# GD32E25x register map
File version: 1.0
CPU: CM23 r1p0, little endian, no MPU, no FPU, 2 interrupt priority bits
Registers are 32-bit, read-write, reset 0x0 unless marked. A register's access mark holds for its fields unless they carry their own. Offsets are from the block's base; [hi:lo] are bit positions; {n}, {i} and the like mark numbered series.

## GPIOB — General-purpose I/Os
Base 0x48000400
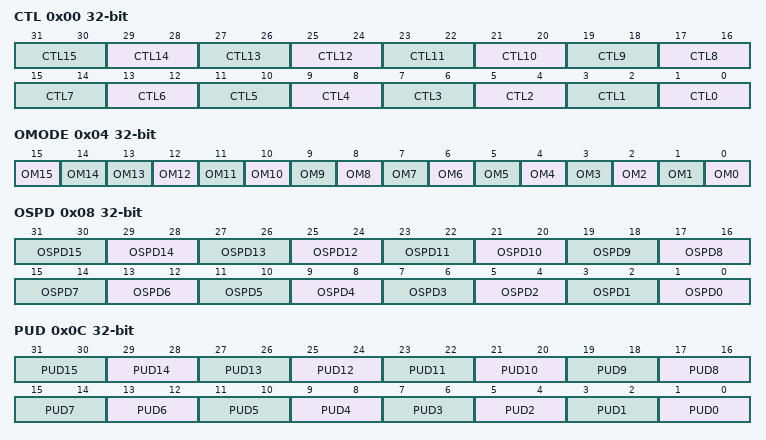
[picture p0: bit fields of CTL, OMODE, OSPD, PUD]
0x00 CTL — GPIO port control register
  [2n+1:2n] CTL{n} (n=0..15) — Pin {n} configuration bits
0x04 OMODE — GPIO port output type register
  [15] OM15 — Pin 15 output mode bit
  [14] OM14 — Pin 15 output mode bit
  [n] OM{n} (n=0..13) — Pin {n} output mode bit
0x08 OSPD — GPIO port output speed register
  [2n+1:2n] OSPD{n} (n=0..15) — Pin {n} output max speed bits
0x0C PUD — GPIO port pull-up/pull-down register
  [2n+1:2n] PUD{n} (n=0..15) — Pin {n} pull-up or pull-down bits
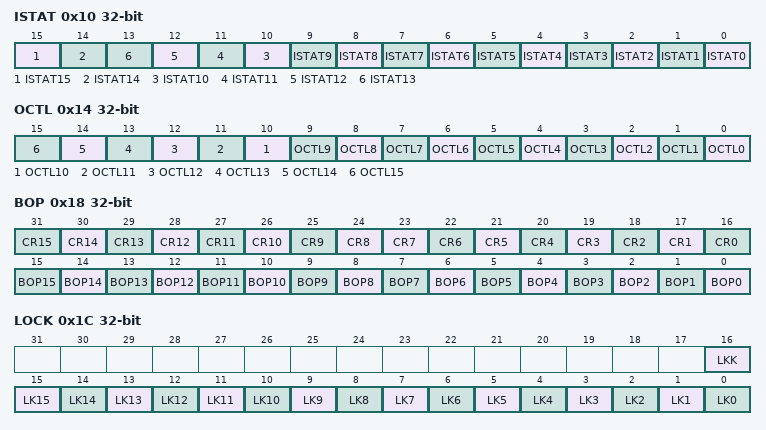
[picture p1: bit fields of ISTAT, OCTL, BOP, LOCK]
0x10 ISTAT ro — GPIO port input data register
  [15] ISTAT15 — Port input status
  [14] ISTAT14 — PPort input status
  [n] ISTAT{n} (n=0..13) — Port input status
0x14 OCTL — GPIO port output data register
  [n] OCTL{n} (n=0..15) — Port output data
0x18 BOP wo — GPIO port bit set/reset register
  [n+16] CR{n} (n=8..15) — Pin {n} reset bit
  [23] CR7 — Pin 7 reset bit)
  [n+16] CR{n} (n=2..6) — Pin {n} reset bit
  [17] CR1 — Pin 2 reset bit
  [16] CR0 — Pin 0 reset bit
  [n] BOP{n} (n=0..15) — Pin {n} set bit
0x1C LOCK — GPIO port configuration lock register
  [16] LKK — Lock key
  [n] LK{n} (n=0..15) — Port A lock bit {n}
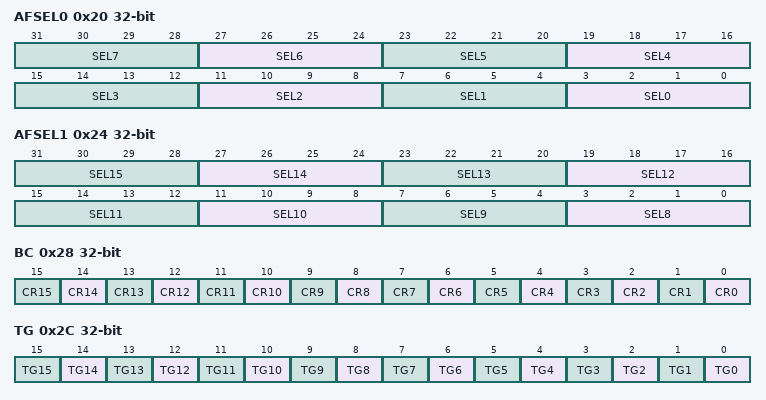
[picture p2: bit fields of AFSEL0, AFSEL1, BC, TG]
0x20 AFSEL0 — GPIO alternate function low register
  [4n+3:4n] SEL{n} (n=0..7) — Pin {n} alternate function selected
0x24 AFSEL1 — GPIO alternate function register 1
  [4n-29:4n-32] SEL{n} (n=8..15) — Pin {n} alternate function selected
0x28 BC wo — Port bit reset register
  [n] CR{n} (n=0..15) — Port cleat bit
0x2C TG wo — Port bit toggle register
  [n] TG{n} (n=0..15) — Port toggle bit
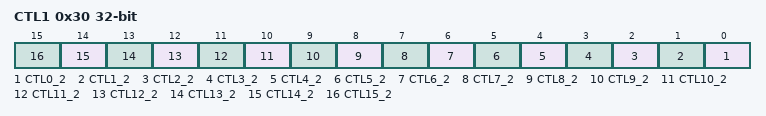
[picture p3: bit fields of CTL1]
0x30 CTL1 — GPIO port control register 1
  [n] CTL{n}_2 (n=0..15) — Pin {n} configuration bits

## GPIOF — General-purpose I/Os
Base 0x48001400
Registers as GPIOB, without LOCK, AFSEL0, AFSEL1; these are added or differ:
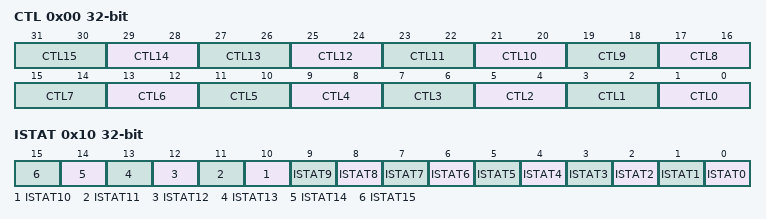
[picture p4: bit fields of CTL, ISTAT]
0x00 CTL — GPIOF port control register
  [2n+1:2n] CTL{n} (n=0..15) — Pin {n} configuration bits
0x10 ISTAT ro — GPIO port input data register
  [n] ISTAT{n} (n=0..15) — Port input data

## GPIOSP — General-purpose I/Os
Base 0x48001000
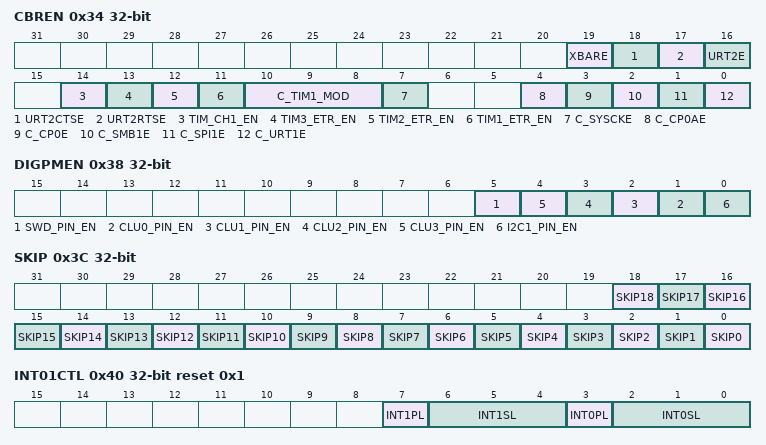
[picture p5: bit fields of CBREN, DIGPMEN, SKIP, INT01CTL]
0x34 CBREN — Crossbar resources enable register
  [19] XBARE — Crossbar Enable
  [18] URT2CTSE — UART2 CTS Input Enable
  [17] URT2RTSE — UART2 RTS Output Enable
  [16] URT2E — UART2 I/O Enable
  [14] TIM_CH1_EN — TIMER14/15/16/17 Channel1 enable
  [13] TIM3_ETR_EN — TIMER3 External triggle enable
  [12] TIM2_ETR_EN — TIMER2 External triggle enable
  [11] TIM1_ETR_EN — TIM1 External Counter Input Enable
  [10:8] C_TIM1_MOD — TIMER1 Module I/O Enable
  [7] C_SYSCKE — SYSCLK Output Enable
  [4] C_CP0AE — Comparator0 Asynchronous Output Enable
  [3] C_CP0E — Comparator0 Output Enable
  [2] C_SMB1E — SMB1 I/O Enable
  [1] C_SPI1E — SPI1 I/O Enable
  [0] C_URT1E — UART1 I/O Enable
0x38 DIGPMEN — Silicon digital function Pin mode enable register
  [5] SWD_PIN_EN — SWDIO port enable
  [n+1] CLU{n}_PIN_EN (n=0..3) — CLU{n} Port Output Enable
  [0] I2C1_PIN_EN — I2C1 Pin mode enable
0x3C SKIP — Crossbar Skip register
  [n] SKIP{n} (n=0..18)
0x40 INT01CTL reset 0x1 — INT0 and INT1 Control Register
  [7] INT1PL — INT1 Polarity
  [6:4] INT1SL — INT1 Port Pin Selection
  [3] INT0PL — INT0 Polarity
  [2:0] INT0SL — INT0 Port Pin Selection
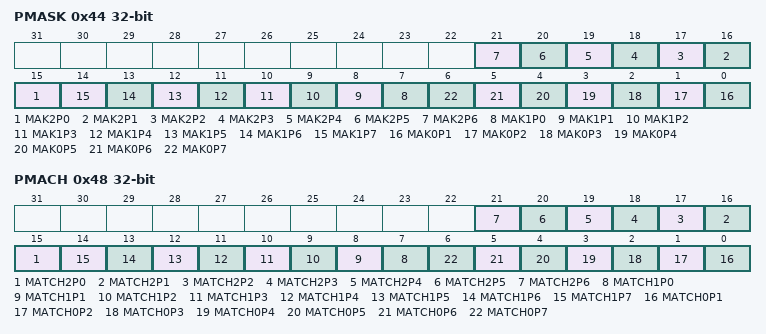
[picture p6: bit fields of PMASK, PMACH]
0x44 PMASK — Port Mask Registers
  [n+15] MAK2P{n} (n=0..6) — 2P{n} MASK Value
  [n+7] MAK1P{n} (n=0..7) — 1P{n} MASK Value
  [n-1] MAK0P{n} (n=1..7) — 0P{n} MASK Value
0x48 PMACH — Port Match Registers
  [n+15] MATCH2P{n} (n=0..6) — 2P{n} MATCH Value
  [n+7] MATCH1P{n} (n=0..7) — 1P{n} MATCH Value
  [n-1] MATCH0P{n} (n=1..7) — 0P{n} MATCH Value

## NVIC — Nested Vectored Interrupt Controller
Base 0xE000E100
{0x0+4i} ISER{i} (i=0..15) — Interrupt Set Enable Register
  [31:0] SETENA
0x80 ICER0 — Interrupt Clear Enable Register
  [31:0] CLRENA
0x84 ICER1 — Interrupt Clear Enable Register
  [31:0] CLRENA
{0x84+4i} ICER{i} (i=2..15) — Interrupt Clear Enable Register
  [31:0] CLRENA
{0x100+4i} ISPR{i} (i=0..15) — Interrupt Set-Pending Register
  [31:0] SETPEND
{0x180+4i} ICPR{i} (i=0..15) — Interrupt Clear-Pending Register
  [31:0] CLRPEND
{0x200+4i} IABR{i} (i=0..15) — Interrupt Active bit Register
  [31:0] IABR
{0x280+4i} ITNS{i} (i=0..15) — Interrupt Active bit Register
  [31:0] ITNS
{0x300+i} IPR{i} 8-bit (i=0..31) — Interrupt Priority Register {i}
  [7:0] PRI_{i:02}
